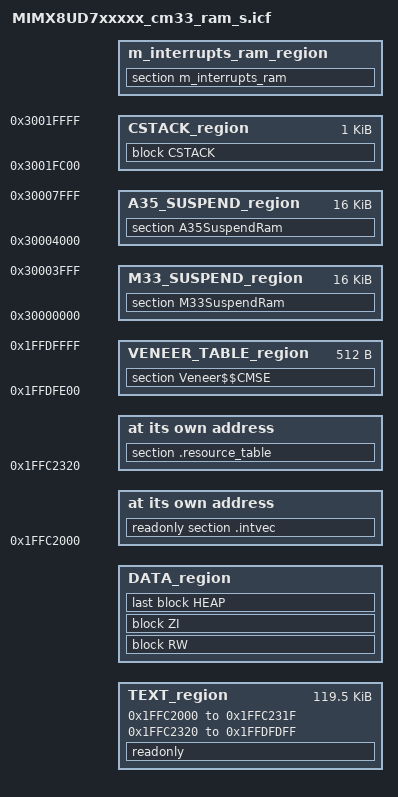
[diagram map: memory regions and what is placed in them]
/*
** ###################################################################
**     Processors:          MIMX8UD7CVP08_cm33
**                          MIMX8UD7DVK08_cm33
**                          MIMX8UD7DVP08_cm33
**
**     Compiler:            IAR ANSI C/C++ Compiler for ARM
**     Reference manual:    IMX8ULPRM, Rev. D, December. 2022
**     Version:             rev. 5.0, 2023-04-27
**     Build:               b230927
**
**     Abstract:
**         Linker file for the IAR ANSI C/C++ Compiler for ARM
**
**     Copyright 2016 Freescale Semiconductor, Inc.
**     Copyright 2016-2023 NXP
**     SPDX-License-Identifier: BSD-3-Clause
**
**     http:                 www.nxp.com
**     mail:                 support@nxp.com
**
** ###################################################################
*/

/* Memory region from [0x0FFC0000-0x0FFC1FFF] is reserved for ROM header */
/* Memory region from [0x20040000-0x2007FFFF] is reserved for A35 ATF */

define symbol __ram_vector_table_size__ =  isdefinedsymbol(__ram_vector_table__) ? 0x00000320 : 0;
define symbol __ram_vector_table_offset__ =  isdefinedsymbol(__ram_vector_table__) ? 0x0000031F : 0;

define symbol m_interrupts_start       = 0x1FFC2000;
define symbol m_interrupts_end         = 0x1FFC231F;

define symbol m_text_start             = 0x1FFC2320;
define symbol m_text_end               = 0x1FFDFDFF;

/* 512B - memory for veneer table (NSC - secure, non-secure callable memory) */
define symbol m_veneer_table_start     = 0x1FFDFE00;
define symbol m_veneer_table_size      = 0x00000200;

define symbol m_m33_suspend_ram_start  = 0x30000000;
define symbol m_m33_suspend_ram_end    = 0x30003FFF;

define symbol m_a35_suspend_ram_start  = 0x30004000;
define symbol m_a35_suspend_ram_end    = 0x30007FFF;

define symbol m_interrupts_ram_start   = 0x30008000;
define symbol m_interrupts_ram_end     = 0x30008000 + __ram_vector_table_offset__;

define symbol m_data_start             = m_interrupts_ram_start + __ram_vector_table_size__;
define symbol m_data_end               = 0x3001FFFF;

/* Sizes */
if (isdefinedsymbol(__stack_size__)) {
  define symbol __size_cstack__        = __stack_size__;
} else {
  define symbol __size_cstack__        = 0x0400;
}

if (isdefinedsymbol(__heap_size__)) {
  define symbol __size_heap__          = __heap_size__;
} else {
  define symbol __size_heap__          = 0x0400;
}

define exported symbol __VECTOR_TABLE  = m_interrupts_start;
define exported symbol __VECTOR_RAM    = isdefinedsymbol(__ram_vector_table__) ? m_interrupts_ram_start : m_interrupts_start;
define exported symbol __RAM_VECTOR_TABLE_SIZE = __ram_vector_table_size__;

define memory mem with size = 4G;
define region TEXT_region = mem:[from m_interrupts_start to m_interrupts_end]
                          | mem:[from m_text_start to m_text_end];
define region DATA_region = mem:[from m_data_start to m_data_end-__size_cstack__];
define region CSTACK_region = mem:[from m_data_end-__size_cstack__+1 to m_data_end];
define region m_interrupts_ram_region = mem:[from m_interrupts_ram_start to m_interrupts_ram_end];
define region M33_SUSPEND_region = mem:[from m_m33_suspend_ram_start to m_m33_suspend_ram_end];
define region A35_SUSPEND_region = mem:[from m_a35_suspend_ram_start to m_a35_suspend_ram_end];
define region VENEER_TABLE_region     = mem:[from m_veneer_table_start to m_veneer_table_start + m_veneer_table_size - 1];

define block CSTACK    with alignment = 8, size = __size_cstack__   { };
define block HEAP      with alignment = 8, size = __size_heap__     { };
define block RW        { readwrite };
define block ZI        { zi };

initialize by copy { readwrite, section .textrw };
do not initialize  { section .noinit, section M33SuspendRam, section A35SuspendRam };

keep{section .resource_table};

place at address mem: m_interrupts_start    { readonly section .intvec };
".resource_table": place at address mem: m_text_start {section .resource_table};
place in TEXT_region                        { readonly };
place in DATA_region                        { block RW };
place in DATA_region                        { block ZI };
place in DATA_region                        { last block HEAP };
place in CSTACK_region                      { block CSTACK };
place in m_interrupts_ram_region            { section m_interrupts_ram };
place in M33_SUSPEND_region                 { section M33SuspendRam };
place in A35_SUSPEND_region                 { section A35SuspendRam };
place in VENEER_TABLE_region                { section Veneer$$CMSE  };
